# CY8C5588AXI_060ES1 register map
File version: 0.1
Registers are 8-bit, read-write, no defined reset value unless marked. A register's access mark holds for its fields unless they carry their own. Offsets are from the block's base; [hi:lo] are bit positions; 'fields as' and 'values as' point back to an identical list.

## TimerResetCtrlBras
Base 0x4000647A
0x00 TimerResetCtrlBras_CONTROL_REG

## TimerResetCtrl
Base 0x4000647C
Registers as TimerResetCtrlBras (with TimerResetCtrlBras read as TimerResetCtrl).

## UART_Rpi — UART
Base 0x40006421
0x00 RX_UART_Rpi_RX_ADDRESS1 — RX Address1 Register
0x10 RX_UART_Rpi_RX_ADDRESS2 — RX Address2 Register
0x1F TX_UART_Rpi_TX_DATA — TX Data Register
0x20 RX_UART_Rpi_RX_DATA — RX Data Register
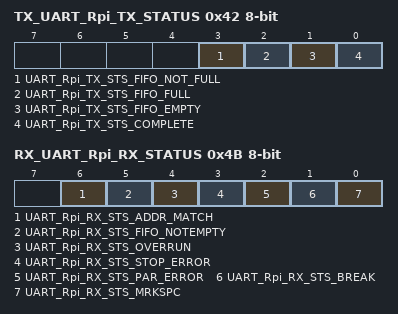
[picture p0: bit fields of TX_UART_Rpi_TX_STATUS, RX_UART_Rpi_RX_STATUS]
0x42 TX_UART_Rpi_TX_STATUS — TX status register
  [3] UART_Rpi_TX_STS_FIFO_NOT_FULL ro, [2] UART_Rpi_TX_STS_FIFO_FULL ro, [1] UART_Rpi_TX_STS_FIFO_EMPTY ro, [0] UART_Rpi_TX_STS_COMPLETE ro
0x4B RX_UART_Rpi_RX_STATUS — RX status register
  [6] UART_Rpi_RX_STS_ADDR_MATCH ro, [5] UART_Rpi_RX_STS_FIFO_NOTEMPTY ro, [4] UART_Rpi_RX_STS_OVERRUN ro, [3] UART_Rpi_RX_STS_STOP_ERROR ro, [2] UART_Rpi_RX_STS_PAR_ERROR ro, [1] UART_Rpi_RX_STS_BREAK ro, [0] UART_Rpi_RX_STS_MRKSPC ro

## UART_XBee — UART
Base 0x40006426
Registers as UART_Rpi (with UART_Rpi read as UART_XBee), without TX_UART_Rpi_TX_DATA, RX_UART_Rpi_RX_STATUS; these are added or differ:
0x22 TX_UART_XBee_TX_DATA — TX Data Register
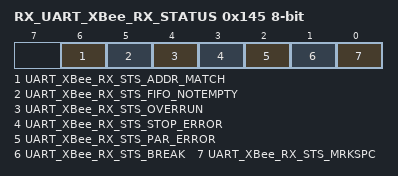
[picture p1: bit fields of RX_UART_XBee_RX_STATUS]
0x145 RX_UART_XBee_RX_STATUS — RX status register
  [6] UART_XBee_RX_STS_ADDR_MATCH ro, [5] UART_XBee_RX_STS_FIFO_NOTEMPTY ro, [4] UART_XBee_RX_STS_OVERRUN ro, [3] UART_XBee_RX_STS_STOP_ERROR ro, [2] UART_XBee_RX_STS_PAR_ERROR ro, [1] UART_XBee_RX_STS_BREAK ro, [0] UART_XBee_RX_STS_MRKSPC ro

## Timer_Bras
Base 0x4000640A
0x00 Timer_Bras_COUNTER — UDB.A0 - Current Down Counter Value
0x20 Timer_Bras_PERIOD — UDB.D0 - Assigned Period
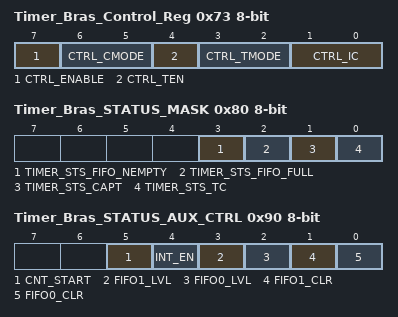
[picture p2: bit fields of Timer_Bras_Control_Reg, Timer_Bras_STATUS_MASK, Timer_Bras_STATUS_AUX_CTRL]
0x73 Timer_Bras_Control_Reg — UDB Control Register - Assigned Control Register Value
  [7] CTRL_ENABLE — Enable the Timer
  [6:5] CTRL_CMODE — Capture Mode
  [4] CTRL_TEN — Trigger Enable Bit
  [3:2] CTRL_TMODE — Trigger Mode
  [1:0] CTRL_IC — Interrupt Count
0x80 Timer_Bras_STATUS_MASK — UDB Status bits Interrupt Mask Enable Register
  [3] TIMER_STS_FIFO_NEMPTY ro — FIFO Empty status
  [2] TIMER_STS_FIFO_FULL ro — FIFO Full Status
  [1] TIMER_STS_CAPT ro — Enables the Interrupt on Capture
  [0] TIMER_STS_TC ro — Enables the Interrupt on TC
0x90 Timer_Bras_STATUS_AUX_CTRL — UDB Auxilliary Control Register
  [5] CNT_START — FIFO0 clear
    0=E_CNT_START0 (Disable counter); 1=E_CNT_START1 (Enable counter)
  [4] INT_EN
    0=E_INT_EN0 (Interrupt disabled); 1=E_INT_EN1 (Interrupt enabled)
  [3] FIFO1_LVL — FIFO level
    0=E_FIFO_LVL_0 (FIFO LVL: input mode: FIFO not full; output mode: FIFO not empty); 1=E_FIFO_LVL_1 (FIFO LVL: input mode: FIFO at least 1/2 empty; output mode: FIFO at least 1/2 full)
  [2] FIFO0_LVL — FIFO level
    values as FIFO1_LVL
  [1] FIFO1_CLR — FIFO1 clear
    0=E_FIFO_CLR_0 (Normal FIFO operation); 1=E_FIFO_CLR_1 (Clear FIFO state)
  [0] FIFO0_CLR — FIFO0 clear
    values as FIFO1_CLR

## Timer_Fin
Base 0x40006402
Registers as Timer_Bras (with Timer_Bras read as Timer_Fin), without Timer_Bras_Control_Reg; these are added or differ:
0x00 Timer_Fin_COUNTER 16-bit — UDB.A0 - Current Down Counter Value
0x20 Timer_Fin_PERIOD 16-bit — UDB.D0 - Assigned Period
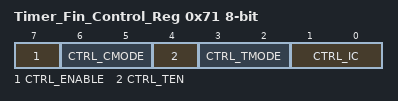
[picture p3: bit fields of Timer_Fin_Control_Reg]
0x71 Timer_Fin_Control_Reg — UDB Control Register - Assigned Control Register Value
  [7] CTRL_ENABLE — Enable the Timer
  [6:5] CTRL_CMODE — Capture Mode
  [4] CTRL_TEN — Trigger Enable Bit
  [3:2] CTRL_TMODE — Trigger Mode
  [1:0] CTRL_IC — Interrupt Count

## Timer_Emp
Base 0x4000640C
0x00 Timer_Emp_COUNTER 16-bit — UDB.A0 - Current Down Counter Value
0x20 Timer_Emp_PERIOD 16-bit — UDB.D0 - Assigned Period
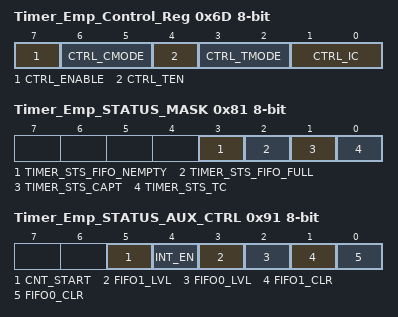
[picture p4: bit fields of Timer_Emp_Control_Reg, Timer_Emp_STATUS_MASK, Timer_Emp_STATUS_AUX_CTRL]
0x6D Timer_Emp_Control_Reg — UDB Control Register - Assigned Control Register Value
  [7] CTRL_ENABLE — Enable the Timer
  [6:5] CTRL_CMODE — Capture Mode
  [4] CTRL_TEN — Trigger Enable Bit
  [3:2] CTRL_TMODE — Trigger Mode
  [1:0] CTRL_IC — Interrupt Count
0x81 Timer_Emp_STATUS_MASK — UDB Status bits Interrupt Mask Enable Register
  [3] TIMER_STS_FIFO_NEMPTY ro — FIFO Empty status
  [2] TIMER_STS_FIFO_FULL ro — FIFO Full Status
  [1] TIMER_STS_CAPT ro — Enables the Interrupt on Capture
  [0] TIMER_STS_TC ro — Enables the Interrupt on TC
0x91 Timer_Emp_STATUS_AUX_CTRL — UDB Auxilliary Control Register
  [5] CNT_START — FIFO0 clear
    0=E_CNT_START0 (Disable counter); 1=E_CNT_START1 (Enable counter)
  [4] INT_EN
    0=E_INT_EN0 (Interrupt disabled); 1=E_INT_EN1 (Interrupt enabled)
  [3] FIFO1_LVL — FIFO level
    0=E_FIFO_LVL_0 (FIFO LVL: input mode: FIFO not full; output mode: FIFO not empty); 1=E_FIFO_LVL_1 (FIFO LVL: input mode: FIFO at least 1/2 empty; output mode: FIFO at least 1/2 full)
  [2] FIFO0_LVL — FIFO level
    values as FIFO1_LVL
  [1] FIFO1_CLR — FIFO1 clear
    0=E_FIFO_CLR_0 (Normal FIFO operation); 1=E_FIFO_CLR_1 (Clear FIFO state)
  [0] FIFO0_CLR — FIFO0 clear
    values as FIFO1_CLR

## UART_Asser — UART
Base 0x40006424
0x00 RX_UART_Asser_RX_ADDRESS1 — RX Address1 Register
0x10 RX_UART_Asser_RX_ADDRESS2 — RX Address2 Register
0x20 RX_UART_Asser_RX_DATA — RX Data Register
0x21 TX_UART_Asser_TX_DATA — TX Data Register
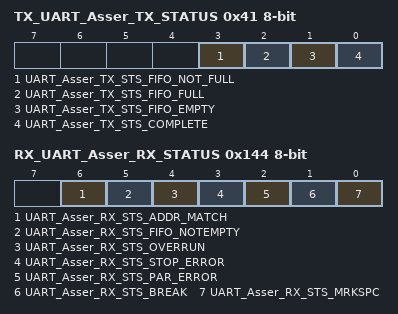
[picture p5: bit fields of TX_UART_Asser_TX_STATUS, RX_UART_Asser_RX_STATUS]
0x41 TX_UART_Asser_TX_STATUS — TX status register
  [3] UART_Asser_TX_STS_FIFO_NOT_FULL ro, [2] UART_Asser_TX_STS_FIFO_FULL ro, [1] UART_Asser_TX_STS_FIFO_EMPTY ro, [0] UART_Asser_TX_STS_COMPLETE ro
0x144 RX_UART_Asser_RX_STATUS — RX status register
  [6] UART_Asser_RX_STS_ADDR_MATCH ro, [5] UART_Asser_RX_STS_FIFO_NOTEMPTY ro, [4] UART_Asser_RX_STS_OVERRUN ro, [3] UART_Asser_RX_STS_STOP_ERROR ro, [2] UART_Asser_RX_STS_PAR_ERROR ro, [1] UART_Asser_RX_STS_BREAK ro, [0] UART_Asser_RX_STS_MRKSPC ro
